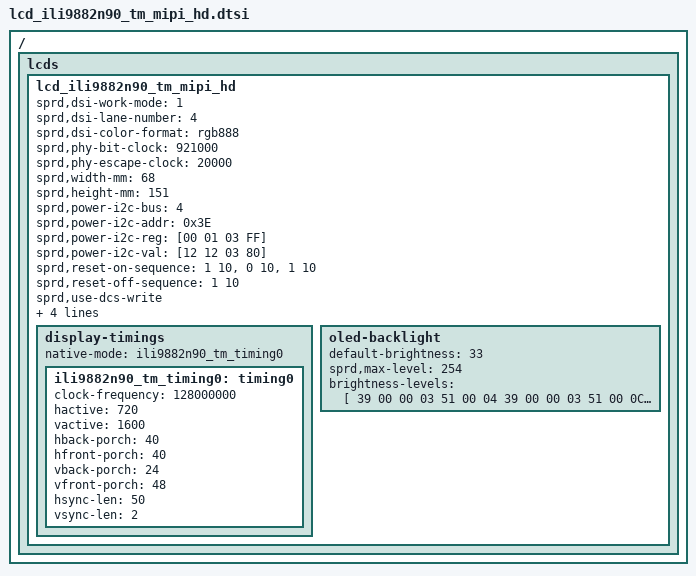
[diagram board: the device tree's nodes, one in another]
/*
 * ili9882n90 tm HD Scaling-Up LCD config dtsi file for spreadtrum
 *
 * Copyright (C) 2018, Spreadtrum Communications Inc.
 *
 * SPDX-License-Identifier: (GPL-2.0+ OR MIT)
 */

/ {
	fragment {
		target-path = "/";
		__overlay__ {
			lcds {
				lcd_ili9882n90_tm_mipi_hd: lcd_ili9882n90_tm_mipi_hd {

					sprd,dsi-work-mode = <1>; /* video burst mode*/
					sprd,dsi-lane-number = <4>;
					sprd,dsi-color-format = "rgb888";

					sprd,phy-bit-clock = <921000>;	/* kbps */
					sprd,phy-escape-clock = <20000>;/* kHz */

					sprd,width-mm = <68>;
					sprd,height-mm = <151>;

					//sprd,esd-check-enable = <1>;
					//sprd,esd-check-mode = <0>;
					//sprd,esd-check-period = <2000>;
					//sprd,esd-check-register = <0xA>;
					//sprd,esd-check-value = <0x9c>;

					sprd,power-i2c-bus = <4>;
        				sprd,power-i2c-addr = <0x3E>;
        				/*sprd,power-i2c-speed = <400000>;*/
        				sprd,power-i2c-reg = [00 01 03 FF];
        				sprd,power-i2c-val = [12 12 03 80];

					sprd,reset-on-sequence = <1 10>, <0 10>, <1 10>;
					sprd,reset-off-sequence = <1 10>;

					sprd,use-dcs-write;

					sprd,initial-command = [
						39 00 00 04 FF 98 82 00
						39 00 00 03 51 07 FF
						15 00 00 02 53 2C
						15 00 00 02 55 01
						39 00 00 03 68 04 01
						05 78 00 01 11
						39 00 00 04 FF 98 82 01
						15 00 00 02 B0 34
						15 00 00 02 B1 34
						15 00 00 02 B2 44
						39 00 00 04 FF 98 82 02
						15 00 00 02 06 69
						15 00 00 02 0B A0
						15 00 00 02 0C 00
						15 00 00 02 0D 16
						15 00 00 02 0E 30
						39 00 00 04 FF 98 82 0B
						15 00 00 02 9A 43
						15 00 00 02 9B 53
						15 00 00 02 9C 03
						15 00 00 02 9D 03
						15 00 00 02 9E 53
						15 00 00 02 9F 53
						15 00 00 02 AB E0
						39 00 00 04 FF 98 82 0C
						15 00 00 02 00 18
						15 00 00 02 01 4F
						15 00 00 02 02 17
						15 00 00 02 03 47
						15 00 00 02 04 18
						15 00 00 02 05 4B
						15 00 00 02 06 19
						15 00 00 02 07 54
						15 00 00 02 08 18
						15 00 00 02 09 4D
						15 00 00 02 0A 19
						15 00 00 02 0B 40
						15 00 00 02 0C 19
						15 00 00 02 0D 51
						15 00 00 02 0E 18
						15 00 00 02 0F 3D
						15 00 00 02 10 18
						15 00 00 02 11 50
						15 00 00 02 12 19
						15 00 00 02 13 43
						15 00 00 02 14 17
						15 00 00 02 15 48
						15 00 00 02 16 19
						15 00 00 02 17 42
						15 00 00 02 18 19
						15 00 00 02 19 52
						15 00 00 02 1A 1A
						15 00 00 02 1B 59
						15 00 00 02 1C 18
						15 00 00 02 1D 3E
						15 00 00 02 1E 19
						15 00 00 02 1F 55
						15 00 00 02 20 19
						15 00 00 02 21 53
						15 00 00 02 22 17
						15 00 00 02 23 49
						15 00 00 02 24 1A
						15 00 00 02 25 57
						15 00 00 02 26 1A
						15 00 00 02 27 5A
						15 00 00 02 28 17
						15 00 00 02 29 45
						15 00 00 02 2A 19 
						15 00 00 02 2B 44
						15 00 00 02 2C 19
						15 00 00 02 2D 41
						15 00 00 02 2E 18
						15 00 00 02 2F 4C
						15 00 00 02 30 19
						15 00 00 02 31 56
						15 00 00 02 32 17
						15 00 00 02 33 46
						15 00 00 02 34 18
						15 00 00 02 35 3C
						15 00 00 02 36 1A
						15 00 00 02 37 58
						15 00 00 02 38 18
						15 00 00 02 39 4E
						15 00 00 02 3A 17
						15 00 00 02 3B 4A
						15 00 00 02 3C 19
						15 00 00 02 3D 3F
						39 00 00 04 FF 98 82 0E
						15 00 00 02 49 C8
						15 00 00 02 11 10
						15 00 00 02 13 10
						15 00 00 02 45 0B
						15 00 00 02 4D 58
						15 00 00 02 00 A3
						15 00 00 02 4B 1E
						15 00 00 02 07 21
						15 00 00 02 C0 01
						15 00 00 02 C1 80
						15 00 00 02 40 07
						15 00 00 02 02 15
						39 00 00 04 FF 98 82 0E
						15 00 00 02 C2 08
						15 00 00 02 C4 44
						15 00 00 02 C5 44
						15 00 00 02 C6 44
						15 00 00 02 C7 40
						15 00 00 02 47 8C
						15 00 00 02 4E 9F
						15 00 00 02 4F 9F
						39 00 00 04 FF 98 82 02
						15 00 00 02 52 48
						15 00 00 02 57 48
						39 00 00 04 FF 98 82 0E
						15 00 00 02 C3 01
						15 00 00 02 46 53
						15 00 00 02 D0 55
						15 00 00 02 D9 59
						15 00 00 02 D8 59
						15 00 00 02 D7 58
						15 00 00 02 D6 58
						15 00 00 02 D5 6A
						15 00 00 02 D4 80
						15 00 00 02 D3 80
						15 00 00 02 D2 01
						15 00 00 02 D1 80
						15 00 00 02 DD 44
						15 00 00 02 DC 44
						15 00 00 02 DB 44
						15 00 00 02 DA 44
						15 00 00 02 E1 08
						15 00 00 02 E2 59
						15 00 00 02 E3 10
						39 00 00 04 FF 98 82 00
						05 14 00 01 29
						];

					sprd,sleep-in-command = [
						05 32 00 01 28
						05 96 00 01 10
						];

					display-timings {
						native-mode = <&ili9882n90_tm_timing0>;

						ili9882n90_tm_timing0: timing0 {
							clock-frequency = <128000000>;
							hactive = <720>;
							vactive = <1600>;
							hback-porch = <40>;
							hfront-porch = <40>;
							vback-porch = <24>;
							vfront-porch = <48>;
							hsync-len = <50>;
							vsync-len = <2>;
						};
					};

					oled-backlight {			
						default-brightness = <33>;	
						sprd,max-level = <254>;
						brightness-levels = [				
            		    	39 00 00 03 51 00 04
							39 00 00 03 51 00 0C
							39 00 00 03 51 00 14
							39 00 00 03 51 00 1C
							39 00 00 03 51 00 25
							39 00 00 03 51 00 2D
							39 00 00 03 51 00 35
							39 00 00 03 51 00 3D
							39 00 00 03 51 00 45
							39 00 00 03 51 00 4D
							39 00 00 03 51 00 55
							39 00 00 03 51 00 5D
							39 00 00 03 51 00 65
							39 00 00 03 51 00 6D
							39 00 00 03 51 00 75
							39 00 00 03 51 00 7D
							39 00 00 03 51 00 85
							39 00 00 03 51 00 8D
							39 00 00 03 51 00 95
							39 00 00 03 51 00 9D
							39 00 00 03 51 00 A5
							39 00 00 03 51 00 AD
							39 00 00 03 51 00 B5
							39 00 00 03 51 00 BD
							39 00 00 03 51 00 C5
							39 00 00 03 51 00 CD
							39 00 00 03 51 00 D5
							39 00 00 03 51 00 DD
							39 00 00 03 51 00 E5
							39 00 00 03 51 00 EE
							39 00 00 03 51 00 F6
							39 00 00 03 51 00 FE
							39 00 00 03 51 01 06
							39 00 00 03 51 01 0E
							39 00 00 03 51 01 16
							39 00 00 03 51 01 1E
							39 00 00 03 51 01 26
							39 00 00 03 51 01 2E
							39 00 00 03 51 01 36
							39 00 00 03 51 01 3E
							39 00 00 03 51 01 46
							39 00 00 03 51 01 4E
							39 00 00 03 51 01 56
							39 00 00 03 51 01 5E
							39 00 00 03 51 01 66
							39 00 00 03 51 01 6E
							39 00 00 03 51 01 76
							39 00 00 03 51 01 7E
							39 00 00 03 51 01 86
							39 00 00 03 51 01 8E
							39 00 00 03 51 01 96
							39 00 00 03 51 01 9E
							39 00 00 03 51 01 A6
							39 00 00 03 51 01 AE
							39 00 00 03 51 01 B7
							39 00 00 03 51 01 BF
							39 00 00 03 51 01 C7
							39 00 00 03 51 01 CF
							39 00 00 03 51 01 D7
							39 00 00 03 51 01 DF
							39 00 00 03 51 01 E7
							39 00 00 03 51 01 EF
							39 00 00 03 51 01 F7
							39 00 00 03 51 01 FF
							39 00 00 03 51 02 07
							39 00 00 03 51 02 0F
							39 00 00 03 51 02 17
							39 00 00 03 51 02 1F
							39 00 00 03 51 02 27
							39 00 00 03 51 02 2F
							39 00 00 03 51 02 37
							39 00 00 03 51 02 3F
							39 00 00 03 51 02 47
							39 00 00 03 51 02 4F
							39 00 00 03 51 02 57
							39 00 00 03 51 02 5F
							39 00 00 03 51 02 67
							39 00 00 03 51 02 6F
							39 00 00 03 51 02 77
							39 00 00 03 51 02 80
							39 00 00 03 51 02 88
							39 00 00 03 51 02 90
							39 00 00 03 51 02 98
							39 00 00 03 51 02 A0
							39 00 00 03 51 02 A8
							39 00 00 03 51 02 B0
							39 00 00 03 51 02 B8
							39 00 00 03 51 02 C0
							39 00 00 03 51 02 C8
							39 00 00 03 51 02 D0
							39 00 00 03 51 02 D8
							39 00 00 03 51 02 E0
							39 00 00 03 51 02 E8
							39 00 00 03 51 02 F0
							39 00 00 03 51 02 F8
							39 00 00 03 51 03 00
							39 00 00 03 51 03 08
							39 00 00 03 51 03 10
							39 00 00 03 51 03 18
							39 00 00 03 51 03 20
							39 00 00 03 51 03 28
							39 00 00 03 51 03 30
							39 00 00 03 51 03 38
							39 00 00 03 51 03 40
							39 00 00 03 51 03 49
							39 00 00 03 51 03 51
							39 00 00 03 51 03 59
							39 00 00 03 51 03 61
							39 00 00 03 51 03 69
							39 00 00 03 51 03 71
							39 00 00 03 51 03 79
							39 00 00 03 51 03 81
							39 00 00 03 51 03 89
							39 00 00 03 51 03 91
							39 00 00 03 51 03 99
							39 00 00 03 51 03 A1
							39 00 00 03 51 03 A9
							39 00 00 03 51 03 B1
							39 00 00 03 51 03 B9
							39 00 00 03 51 03 C1
							39 00 00 03 51 03 C9
							39 00 00 03 51 03 D1
							39 00 00 03 51 03 D9
							39 00 00 03 51 03 E1
							39 00 00 03 51 03 E9
							39 00 00 03 51 03 F1
							39 00 00 03 51 03 F9
							39 00 00 03 51 04 01
							39 00 00 03 51 04 09
							39 00 00 03 51 04 12
							39 00 00 03 51 04 1A
							39 00 00 03 51 04 22
							39 00 00 03 51 04 2A
							39 00 00 03 51 04 32
							39 00 00 03 51 04 3A
							39 00 00 03 51 04 42
							39 00 00 03 51 04 4A
							39 00 00 03 51 04 52
							39 00 00 03 51 04 5A
							39 00 00 03 51 04 62
							39 00 00 03 51 04 6A
							39 00 00 03 51 04 72
							39 00 00 03 51 04 7A
							39 00 00 03 51 04 82
							39 00 00 03 51 04 8A
							39 00 00 03 51 04 92
							39 00 00 03 51 04 9A
							39 00 00 03 51 04 A2
							39 00 00 03 51 04 AA
							39 00 00 03 51 04 B2
							39 00 00 03 51 04 BA
							39 00 00 03 51 04 C2
							39 00 00 03 51 04 CA
							39 00 00 03 51 04 D2
							39 00 00 03 51 04 DB
							39 00 00 03 51 04 E3
							39 00 00 03 51 04 EB
							39 00 00 03 51 04 F3
							39 00 00 03 51 04 FB
							39 00 00 03 51 05 03
							39 00 00 03 51 05 0B
							39 00 00 03 51 05 13
							39 00 00 03 51 05 1B
							39 00 00 03 51 05 23
							39 00 00 03 51 05 2B
							39 00 00 03 51 05 33
							39 00 00 03 51 05 3B
							39 00 00 03 51 05 43
							39 00 00 03 51 05 4B
							39 00 00 03 51 05 53
							39 00 00 03 51 05 5B
							39 00 00 03 51 05 63
							39 00 00 03 51 05 6B
							39 00 00 03 51 05 73
							39 00 00 03 51 05 7B
							39 00 00 03 51 05 83
							39 00 00 03 51 05 8B
							39 00 00 03 51 05 93
							39 00 00 03 51 05 9B
							39 00 00 03 51 05 A4
							39 00 00 03 51 05 AC
							39 00 00 03 51 05 B4
							39 00 00 03 51 05 BC
							39 00 00 03 51 05 C4
							39 00 00 03 51 05 CC
							39 00 00 03 51 05 D4
							39 00 00 03 51 05 DC
							39 00 00 03 51 05 E4
							39 00 00 03 51 05 EC
							39 00 00 03 51 05 F4
							39 00 00 03 51 05 FC
							39 00 00 03 51 06 04
							39 00 00 03 51 06 0C
							39 00 00 03 51 06 14
							39 00 00 03 51 06 1C
							39 00 00 03 51 06 24
							39 00 00 03 51 06 2C
							39 00 00 03 51 06 34
							39 00 00 03 51 06 3C
							39 00 00 03 51 06 44
							39 00 00 03 51 06 4C
							39 00 00 03 51 06 54
							39 00 00 03 51 06 5C
							39 00 00 03 51 06 64
							39 00 00 03 51 06 6D
							39 00 00 03 51 06 75
							39 00 00 03 51 06 7D
							39 00 00 03 51 06 85
							39 00 00 03 51 06 8D
							39 00 00 03 51 06 95
							39 00 00 03 51 06 9D
							39 00 00 03 51 06 A5
							39 00 00 03 51 06 AD
							39 00 00 03 51 06 B5
							39 00 00 03 51 06 BD
							39 00 00 03 51 06 C5
							39 00 00 03 51 06 CD
							39 00 00 03 51 06 D5
							39 00 00 03 51 06 DD
							39 00 00 03 51 06 E5
							39 00 00 03 51 06 ED
							39 00 00 03 51 06 F5
							39 00 00 03 51 06 FD
							39 00 00 03 51 07 05
							39 00 00 03 51 07 0D
							39 00 00 03 51 07 15
							39 00 00 03 51 07 1D
							39 00 00 03 51 07 25
							39 00 00 03 51 07 2D
							39 00 00 03 51 07 36
							39 00 00 03 51 07 3E
							39 00 00 03 51 07 46
							39 00 00 03 51 07 4E
							39 00 00 03 51 07 56
							39 00 00 03 51 07 5E
							39 00 00 03 51 07 66
							39 00 00 03 51 07 6E
							39 00 00 03 51 07 76
							39 00 00 03 51 07 7E
							39 00 00 03 51 07 86
							39 00 00 03 51 07 8E
							39 00 00 03 51 07 96
							39 00 00 03 51 07 9E
							39 00 00 03 51 07 A6
							39 00 00 03 51 07 AE
							39 00 00 03 51 07 B6
							39 00 00 03 51 07 BE
							39 00 00 03 51 07 C6
							39 00 00 03 51 07 CE
							39 00 00 03 51 07 D6
							39 00 00 03 51 07 DE
							39 00 00 03 51 07 E6
							39 00 00 03 51 07 EE
							39 00 00 03 51 07 F6
							39 00 00 03 51 07 FF
						];
					};
				};
			};
		};
	};
};
